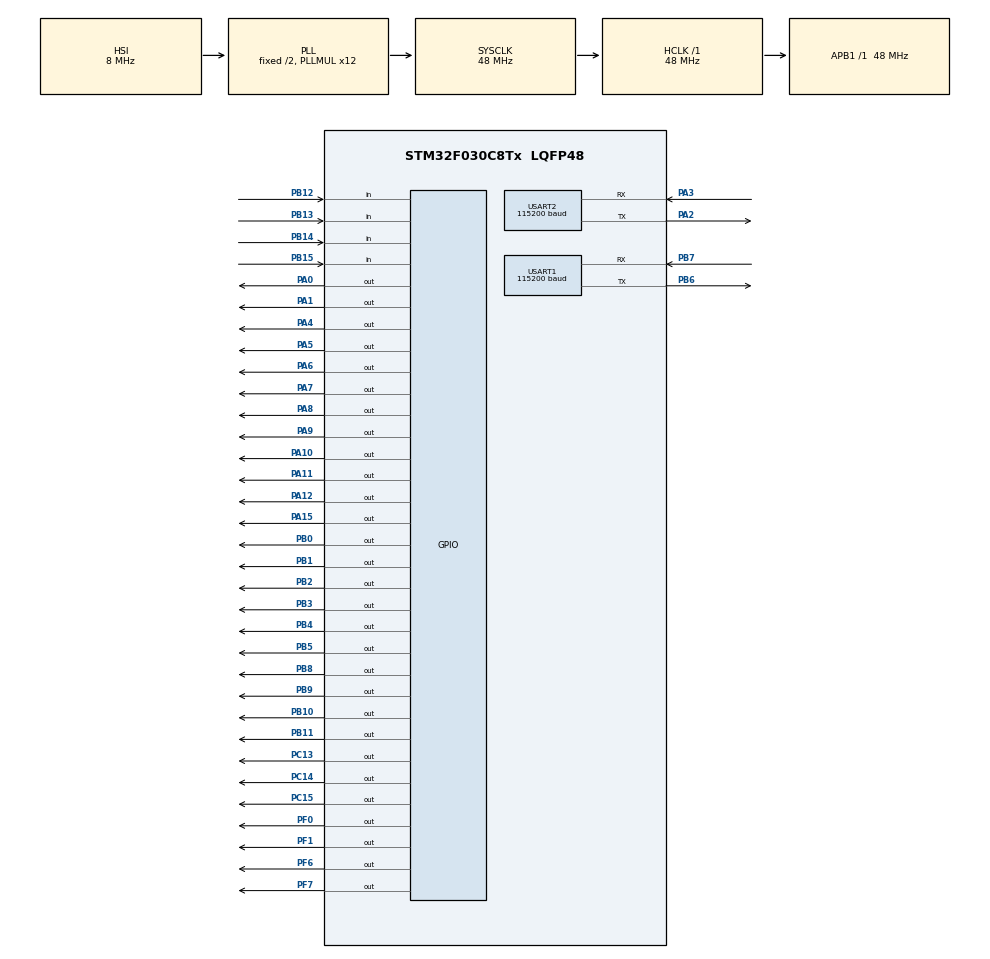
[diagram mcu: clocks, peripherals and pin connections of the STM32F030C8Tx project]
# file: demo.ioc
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Dma.Request0=USART2_TX
Dma.Request1=USART2_RX
Dma.Request2=USART1_TX
Dma.Request3=USART1_RX
Dma.USART1_RX.3.Direction=DMA_PERIPH_TO_MEMORY
Dma.USART1_RX.3.Instance=DMA1_Channel3
Dma.USART1_RX.3.MemDataAlignment=DMA_MDATAALIGN_BYTE
Dma.USART1_RX.3.MemInc=DMA_MINC_ENABLE
Dma.USART1_RX.3.Mode=DMA_NORMAL
Dma.USART1_RX.3.PeriphDataAlignment=DMA_PDATAALIGN_BYTE
Dma.USART1_RX.3.PeriphInc=DMA_PINC_DISABLE
Dma.USART1_RX.3.Priority=DMA_PRIORITY_HIGH
Dma.USART1_TX.2.Direction=DMA_MEMORY_TO_PERIPH
Dma.USART1_TX.2.Instance=DMA1_Channel2
Dma.USART1_TX.2.MemDataAlignment=DMA_MDATAALIGN_BYTE
Dma.USART1_TX.2.MemInc=DMA_MINC_ENABLE
Dma.USART1_TX.2.Mode=DMA_NORMAL
Dma.USART1_TX.2.PeriphDataAlignment=DMA_PDATAALIGN_BYTE
Dma.USART1_TX.2.PeriphInc=DMA_PINC_DISABLE
Dma.USART1_TX.2.Priority=DMA_PRIORITY_LOW
Dma.USART2_RX.1.Direction=DMA_PERIPH_TO_MEMORY
Dma.USART2_RX.1.Instance=DMA1_Channel5
Dma.USART2_RX.1.MemDataAlignment=DMA_MDATAALIGN_BYTE
Dma.USART2_RX.1.MemInc=DMA_MINC_ENABLE
Dma.USART2_RX.1.Mode=DMA_NORMAL
Dma.USART2_RX.1.PeriphDataAlignment=DMA_PDATAALIGN_BYTE
Dma.USART2_RX.1.PeriphInc=DMA_PINC_DISABLE
Dma.USART2_RX.1.Priority=DMA_PRIORITY_HIGH
Dma.USART2_TX.0.Direction=DMA_MEMORY_TO_PERIPH
Dma.USART2_TX.0.Instance=DMA1_Channel4
Dma.USART2_TX.0.MemDataAlignment=DMA_MDATAALIGN_BYTE
Dma.USART2_TX.0.MemInc=DMA_MINC_ENABLE
Dma.USART2_TX.0.Mode=DMA_NORMAL
Dma.USART2_TX.0.PeriphDataAlignment=DMA_PDATAALIGN_BYTE
Dma.USART2_TX.0.PeriphInc=DMA_PINC_DISABLE
Dma.USART2_TX.0.Priority=DMA_PRIORITY_LOW
IWDG.Prescaler=IWDG_PRESCALER_256
IWDG.Reload=1000
Mcu.Family=STM32F0
Mcu.Name=STM32F030C8Tx
Mcu.Package=LQFP48
NVIC.DMA1_Channel2_3_IRQn=true\:0\:0\:false\:false\:true\:false\:true
NVIC.DMA1_Channel4_5_IRQn=true\:0\:0\:true\:false\:true\:false\:true
NVIC.TIM3_IRQn=true\:3\:0\:true\:false\:true\:true\:true
NVIC.TIM6_IRQn=true\:3\:0\:true\:false\:true\:true\:true
NVIC.USART1_IRQn=true\:1\:0\:true\:false\:true\:true\:true
NVIC.USART2_IRQn=true\:2\:0\:true\:false\:true\:true\:true
PA0.GPIO_PuPd=GPIO_PULLUP
PA0.PinState=GPIO_PIN_SET
PA0.Signal=GPIO_Output
PA1.PinState=GPIO_PIN_SET
PA1.Signal=GPIO_Output
PA10.GPIO_PuPd=GPIO_PULLUP
PA10.PinState=GPIO_PIN_SET
PA10.Signal=GPIO_Output
PA11.GPIO_PuPd=GPIO_PULLUP
PA11.PinState=GPIO_PIN_SET
PA11.Signal=GPIO_Output
PA12.GPIO_PuPd=GPIO_PULLUP
PA12.PinState=GPIO_PIN_SET
PA12.Signal=GPIO_Output
PA13.Mode=Serial_Wire
PA13.Signal=SYS_SWDIO
PA14.Mode=Serial_Wire
PA14.Signal=SYS_SWCLK
PA15.GPIO_PuPd=GPIO_PULLUP
PA15.PinState=GPIO_PIN_SET
PA15.Signal=GPIO_Output
PA2.Mode=Asynchronous
PA2.Signal=USART2_TX
PA3.Mode=Asynchronous
PA3.Signal=USART2_RX
PA4.GPIO_PuPd=GPIO_PULLUP
PA4.PinState=GPIO_PIN_SET
PA4.Signal=GPIO_Output
PA5.GPIO_PuPd=GPIO_PULLUP
PA5.PinState=GPIO_PIN_SET
PA5.Signal=GPIO_Output
PA6.GPIO_PuPd=GPIO_PULLDOWN
PA6.PinState=GPIO_PIN_SET
PA6.Signal=GPIO_Output
PA7.GPIO_PuPd=GPIO_PULLUP
PA7.PinState=GPIO_PIN_SET
PA7.Signal=GPIO_Output
PA8.GPIO_PuPd=GPIO_PULLUP
PA8.PinState=GPIO_PIN_RESET
PA8.Signal=GPIO_Output
PA9.GPIO_PuPd=GPIO_PULLUP
PA9.PinState=GPIO_PIN_SET
PA9.Signal=GPIO_Output
PB0.GPIO_PuPd=GPIO_PULLUP
PB0.PinState=GPIO_PIN_SET
PB0.Signal=GPIO_Output
PB1.GPIO_PuPd=GPIO_PULLUP
PB1.PinState=GPIO_PIN_SET
PB1.Signal=GPIO_Output
PB10.GPIO_PuPd=GPIO_PULLUP
PB10.PinState=GPIO_PIN_SET
PB10.Signal=GPIO_Output
PB11.GPIO_PuPd=GPIO_PULLUP
PB11.PinState=GPIO_PIN_SET
PB11.Signal=GPIO_Output
PB12.GPIO_PuPd=GPIO_PULLUP
PB12.Signal=GPIO_Input
PB13.GPIO_PuPd=GPIO_PULLUP
PB13.Signal=GPIO_Input
PB14.GPIO_PuPd=GPIO_PULLUP
PB14.Signal=GPIO_Input
PB15.GPIO_PuPd=GPIO_PULLUP
PB15.Signal=GPIO_Input
PB2.GPIO_PuPd=GPIO_PULLUP
PB2.PinState=GPIO_PIN_SET
PB2.Signal=GPIO_Output
PB3.GPIO_PuPd=GPIO_PULLUP
PB3.PinState=GPIO_PIN_SET
PB3.Signal=GPIO_Output
PB4.GPIO_PuPd=GPIO_PULLUP
PB4.PinState=GPIO_PIN_SET
PB4.Signal=GPIO_Output
PB5.GPIO_PuPd=GPIO_PULLUP
PB5.PinState=GPIO_PIN_SET
PB5.Signal=GPIO_Output
PB6.GPIO_PuPd=GPIO_PULLUP
PB6.GPIO_Speed=GPIO_SPEED_FREQ_HIGH
PB6.Mode=Asynchronous
PB6.Signal=USART1_TX
PB7.GPIO_PuPd=GPIO_PULLUP
PB7.Mode=Asynchronous
PB7.Signal=USART1_RX
PB8.GPIO_PuPd=GPIO_PULLUP
PB8.PinState=GPIO_PIN_SET
PB8.Signal=GPIO_Output
PB9.GPIO_PuPd=GPIO_PULLUP
PB9.PinState=GPIO_PIN_SET
PB9.Signal=GPIO_Output
PC13.GPIO_PuPd=GPIO_PULLUP
PC13.PinState=GPIO_PIN_SET
PC13.Signal=GPIO_Output
PC14-OSC32_IN.GPIO_PuPd=GPIO_PULLUP
PC14-OSC32_IN.PinState=GPIO_PIN_SET
PC14-OSC32_IN.Signal=GPIO_Output
PC15-OSC32_OUT.GPIO_PuPd=GPIO_PULLUP
PC15-OSC32_OUT.PinState=GPIO_PIN_SET
PC15-OSC32_OUT.Signal=GPIO_Output
PF0-OSC_IN.GPIO_PuPd=GPIO_PULLUP
PF0-OSC_IN.PinState=GPIO_PIN_SET
PF0-OSC_IN.Signal=GPIO_Output
PF1-OSC_OUT.GPIO_PuPd=GPIO_PULLUP
PF1-OSC_OUT.PinState=GPIO_PIN_SET
PF1-OSC_OUT.Signal=GPIO_Output
PF6.GPIO_PuPd=GPIO_PULLUP
PF6.PinState=GPIO_PIN_SET
PF6.Signal=GPIO_Output
PF7.GPIO_PuPd=GPIO_PULLUP
PF7.PinState=GPIO_PIN_SET
PF7.Signal=GPIO_Output
ProjectManager.HeapSize=0x200
ProjectManager.StackSize=0x400
ProjectManager.TargetToolchain=MDK-ARM V5
RCC.AHBFreq_Value=48000000
RCC.APB1Freq_Value=48000000
RCC.APB1TimFreq_Value=48000000
RCC.HCLKFreq_Value=48000000
RCC.PLLMUL=RCC_PLL_MUL12
RCC.SYSCLKFreq_VALUE=48000000
RCC.SYSCLKSource=RCC_SYSCLKSOURCE_PLLCLK
TIM3.Period=99
TIM3.Prescaler=47
TIM6.Period=999
TIM6.Prescaler=47
USART1.BaudRate=115200
USART1.VirtualMode-Asynchronous=VM_ASYNC
USART2.BaudRate=115200
USART2.VirtualMode-Asynchronous=VM_ASYNC
VP_IWDG_VS_IWDG.Mode=IWDG_Activate
VP_TIM3_VS_ClockSourceINT.Mode=Internal
VP_TIM6_VS_ClockSourceINT.Mode=Enable_Timer
board=light_sensor

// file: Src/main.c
/* USER CODE BEGIN Header */
/**
  ******************************************************************************
  * @file           : main.c
  * @brief          : Main program body
  ******************************************************************************
  * @attention
  *
  * <h2><center>&copy; Copyright (c) 2019 STMicroelectronics.
  * All rights reserved.</center></h2>
  *
  * This software component is licensed by ST under BSD 3-Clause license,
  * the "License"; You may not use this file except in compliance with the
  * License. You may obtain a copy of the License at:
  *                        opensource.org/licenses/BSD-3-Clause
  *
  ******************************************************************************
  */
/* USER CODE END Header */

#include "main.h"
#include "dma.h"
#include "iwdg.h"
#include "tim.h"
#include "usart.h"
#include "gpio.h"

/* USER CODE BEGIN Includes */
#include "global.h"
/* USER CODE END Includes */

/* USER CODE BEGIN PV */
/* Private variables ---------------------------------------------------------*/

/* USER CODE END PV */

void SystemClock_Config(void);
/* USER CODE BEGIN PFP */
/* Private function prototypes -----------------------------------------------*/

/* USER CODE END PFP */

int main(void)
{

  /* MCU Configuration--------------------------------------------------------*/

  /* Reset of all peripherals, Initializes the Flash interface and the Systick. */
  HAL_Init();

  /* Configure the system clock */
  SystemClock_Config();

  /* Initialize all configured peripherals */
  MX_GPIO_Init();
  MX_DMA_Init();
  MX_USART1_UART_Init();
  MX_TIM3_Init();
  MX_USART2_UART_Init();
  MX_IWDG_Init();
  MX_TIM6_Init();

  /* Infinite loop */
  while (1)
  {

    /* USER CODE BEGIN 3 */
    Main_Loop();//主函数大循环
  }
  /* USER CODE END 3 */
}

void SystemClock_Config(void)
{
  RCC_OscInitTypeDef RCC_OscInitStruct = {0};
  RCC_ClkInitTypeDef RCC_ClkInitStruct = {0};
  RCC_PeriphCLKInitTypeDef PeriphClkInit = {0};

  /** Initializes the CPU, AHB and APB busses clocks
  */
  RCC_OscInitStruct.OscillatorType = RCC_OSCILLATORTYPE_HSI|RCC_OSCILLATORTYPE_LSI;
  RCC_OscInitStruct.HSIState = RCC_HSI_ON;
  RCC_OscInitStruct.HSICalibrationValue = RCC_HSICALIBRATION_DEFAULT;
  RCC_OscInitStruct.LSIState = RCC_LSI_ON;
  RCC_OscInitStruct.PLL.PLLState = RCC_PLL_ON;
  RCC_OscInitStruct.PLL.PLLSource = RCC_PLLSOURCE_HSI;
  RCC_OscInitStruct.PLL.PLLMUL = RCC_PLL_MUL12;
  RCC_OscInitStruct.PLL.PREDIV = RCC_PREDIV_DIV1;
  if (HAL_RCC_OscConfig(&RCC_OscInitStruct) != HAL_OK)
  {
    Error_Handler();
  }
  /** Initializes the CPU, AHB and APB busses clocks
  */
  RCC_ClkInitStruct.ClockType = RCC_CLOCKTYPE_HCLK|RCC_CLOCKTYPE_SYSCLK
                              |RCC_CLOCKTYPE_PCLK1;
  RCC_ClkInitStruct.SYSCLKSource = RCC_SYSCLKSOURCE_PLLCLK;
  RCC_ClkInitStruct.AHBCLKDivider = RCC_SYSCLK_DIV1;
  RCC_ClkInitStruct.APB1CLKDivider = RCC_HCLK_DIV1;

  if (HAL_RCC_ClockConfig(&RCC_ClkInitStruct, FLASH_LATENCY_1) != HAL_OK)
  {
    Error_Handler();
  }
  PeriphClkInit.PeriphClockSelection = RCC_PERIPHCLK_USART1;
  PeriphClkInit.Usart1ClockSelection = RCC_USART1CLKSOURCE_PCLK1;
  if (HAL_RCCEx_PeriphCLKConfig(&PeriphClkInit) != HAL_OK)
  {
    Error_Handler();
  }
}

void Error_Handler(void)
{
  while(1)
  {
  }
}

/************************ (C) COPYRIGHT STMicroelectronics *****END OF FILE****/
